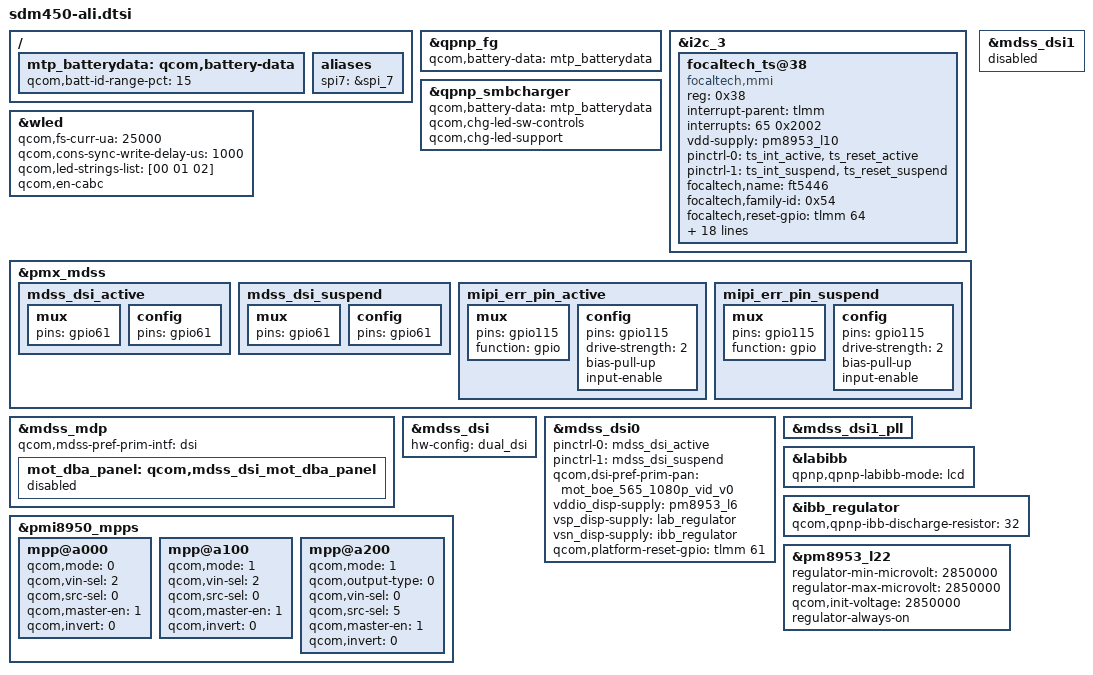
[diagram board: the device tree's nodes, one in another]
/*
 * Copyright (c) 2017-2018, The Linux Foundation. All rights reserved.
 *
 * This program is free software; you can redistribute it and/or modify
 * it under the terms of the GNU General Public License version 2 and
 * only version 2 as published by the Free Software Foundation.
 *
 * This program is distributed in the hope that it will be useful,
 * but WITHOUT ANY WARRANTY; without even the implied warranty of
 * MERCHANTABILITY or FITNESS FOR A PARTICULAR PURPOSE.  See the
 * GNU General Public License for more details.
 */

#include "sdm450-moto-common.dtsi"
#include "sdm450-ali-pinctrl.dtsi"
#include "msm8953-camera-sensor-mtp.dtsi"
#include "dsi-panel-mot-boe-565-1080p-vid.dtsi"
#include "dsi-panel-mot-tianma-565-1080p-vid.dtsi"
#include "dsi-panel-mot-auo-565-1080p-vid.dtsi"
#include "dsi-panel-mot-dummy-qhd-video.dtsi"
#include "sdm450-ali-audio.dtsi"

/{
	mtp_batterydata: qcom,battery-data {
		qcom,batt-id-range-pct = <15>;
		#include "batterydata-itech-3000mah.dtsi"
		#include "batterydata-ascent-3450mAh.dtsi"
	};
	aliases {
		spi7 = &spi_7;
	};
};

&qpnp_fg {
	qcom,battery-data = <&mtp_batterydata>;
};

&i2c_3 { /* BLSP1 QUP3 */
	status = "okay";
	focaltech_ts@38 {
		compatible = "focaltech,mmi";
		reg = <0x38>;
		interrupt-parent = <&tlmm>;
		interrupts = <65 0x2002>;
		vdd-supply = <&pm8953_l10>;
		pinctrl-names = "pmx_ts_active", "pmx_ts_suspend";
		pinctrl-0 = <&ts_int_active &ts_reset_active>;
		pinctrl-1 = <&ts_int_suspend &ts_reset_suspend>;
		focaltech,name = "ft5446";
		focaltech,family-id = <0x54>;
		focaltech,reset-gpio = <&tlmm 64 0x00>;
		focaltech,irq-gpio = <&tlmm 65 0x2008>;
		focaltech,display-coords = <0 0 1080 2160>;
		focaltech,panel-coords = <0 0 1080 2160>;
		focaltech,i2c-pull-up;
		focaltech,group-id = <1>;
		focaltech,hard-reset-delay-ms = <20>;
		focaltech,soft-reset-delay-ms = <200>;
		focaltech,num-max-touches = <10>;
		focaltech,fw-delay-aa-ms = <2>;
		focaltech,fw-delay-55-ms = <2>;
		focaltech,fw-upgrade-id1 = <0x54>;
		focaltech,fw-upgrade-id2 = <0x22>;
		focaltech,fw-delay-readid-ms = <20>;
		focaltech,fw-delay-era-flsh-ms = <2000>;
		focaltech,resume-in-workqueue;
		focaltech,ignore-id-check;
		focaltech,vendor_ids = <0x01 0x02 0x04>;
		focaltech,vendor_names ="ofilm", "toptouch", "biel";
	};
};

&qpnp_smbcharger {
	qcom,battery-data = <&mtp_batterydata>;
	qcom,chg-led-sw-controls;
	qcom,chg-led-support;
};

&wled {
	qcom,fs-curr-ua = <25000>;
	qcom,cons-sync-write-delay-us = <1000>;
	qcom,led-strings-list = [00 01 02];
	qcom,en-cabc;
};

&pmx_mdss {
	mdss_dsi_active {
		mux {
			pins = "gpio61";
		};

		config {
			pins = "gpio61";
		};
	};

	mdss_dsi_suspend {
		mux {
			pins = "gpio61";
		};

		config {
			pins = "gpio61";
		};
	};

	mipi_err_pin_active: mipi_err_pin_active {
		mux {
			pins = "gpio115";
			function = "gpio";
		};

		config {
			pins = "gpio115";
			drive-strength = <2>; /* 2 mA */
			bias-pull-up; /* pull up */
			input-enable;
		};
	};

	mipi_err_pin_suspend: mipi_err_pin_suspend {
		mux {
			pins = "gpio115";
			function = "gpio";
		};

		config {
			pins = "gpio115";
			drive-strength = <2>; /* 2 mA */
			bias-pull-up; /* pull up */
			input-enable;
		};
	};
};

&mdss_mdp {
	qcom,mdss-pref-prim-intf = "dsi";

	mot_dba_panel: qcom,mdss_dsi_mot_dba_panel{
		#include "dsi-panel-mot-mod-fwvga-video-common.dtsi"
	};
};

&mdss_dsi {
	hw-config = "dual_dsi";
};

&mdss_dsi0 {
	pinctrl-names = "mdss_default", "mdss_sleep";
	pinctrl-0 = <&mdss_dsi_active>;
	pinctrl-1 = <&mdss_dsi_suspend>;

	qcom,dsi-pref-prim-pan = <&mot_boe_565_1080p_vid_v0>;

	/delete-property/ vdd-supply;
	vddio_disp-supply = <&pm8953_l6>;
	vsp_disp-supply = <&lab_regulator>;
	vsn_disp-supply = <&ibb_regulator>;

	qcom,platform-reset-gpio = <&tlmm 61 0>;
};

&mdss_dsi1 {
	status = "disabled";
};

&mdss_dsi1_pll {
	/delete-property/ qcom,dsi-pll-ssc-en;
	/delete-property/ qcom,dsi-pll-ssc-mode;
};

&mot_dba_panel {
	status = "disabled";
};


/* display boost and inverting boost regulators */
&labibb {
	status = "ok";
	qpnp,qpnp-labibb-mode = "lcd";
};

&ibb_regulator {
	qcom,qpnp-ibb-discharge-resistor = <32>;
};

&pmi8950_mpps {
	mpp@a000 { /* MPP 1 - MOD_BP_OC_FAULT_N */
		qcom,mode = <0>;	/* Input */
		qcom,vin-sel = <2>;	/* 1.8 */
		qcom,src-sel = <0>;	/* GPIO */
		qcom,master-en = <1>;	/* Enable GPIO */
		qcom,invert = <0>;	/* Output low */
		status = "okay";
	};
	mpp@a100 { /* MPP 2 - MOD_F_FLASH */
		qcom,mode = <1>;	/* Digital output */
		qcom,vin-sel = <2>;	/* 1.8 */
		qcom,src-sel = <0>;	/* GPIO */
		qcom,master-en = <1>;	/* Enable GPIO */
		qcom,invert = <0>;	/* Output low */
		status = "okay";
	};
	mpp@a200 { /* MPP 3 - DISP_AVDD_SHUTDOWN */
		qcom,mode = <1>;		/* Digital output */
		qcom,output-type = <0>;		/* CMOS logic */
		qcom,vin-sel = <0>;
		qcom,src-sel = <5>;		/* DTEST2 */
		qcom,master-en = <1>;		/* Enable GPIO */
		qcom,invert = <0>;
		status = "okay";
	};
};

&pm8953_l22 {
	regulator-min-microvolt = <2850000>;
	regulator-max-microvolt = <2850000>;
	qcom,init-voltage = <2850000>;
	regulator-always-on;
};
